# STM32L15xxE register map
File version: 1.0
CPU: 
Registers are 32-bit, read-write, reset 0x0 unless marked. A register's access mark holds for its fields unless they carry their own. Offsets are from the block's base; [hi:lo] are bit positions; {n}, {i} and the like mark numbered series.

## LCD — Liquid crystal display controller
Base 0x40002400
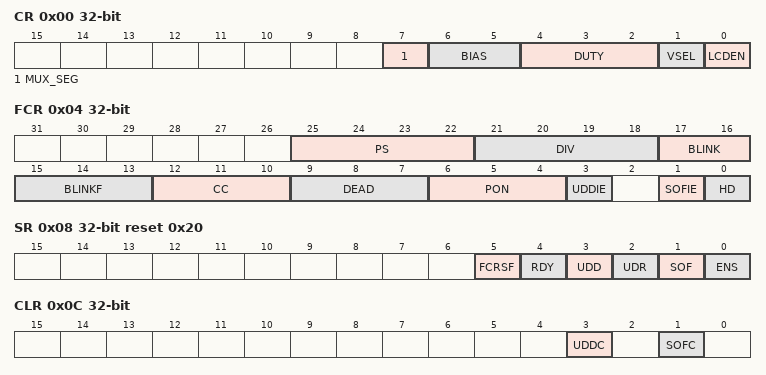
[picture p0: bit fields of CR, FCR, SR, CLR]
0x00 CR — control register
  [7] MUX_SEG — Mux segment enable
  [6:5] BIAS — Bias selector
  [4:2] DUTY — Duty selection
  [1] VSEL — Voltage source selection
  [0] LCDEN — LCD controller enable
0x04 FCR — frame control register
  [25:22] PS — PS 16-bit prescaler
  [21:18] DIV — DIV clock divider
  [17:16] BLINK — Blink mode selection
  [15:13] BLINKF — Blink frequency selection
  [12:10] CC — Contrast control
  [9:7] DEAD — Dead time duration
  [6:4] PON — Pulse ON duration
  [3] UDDIE — Update display done interrupt enable
  [1] SOFIE — Start of frame interrupt enable
  [0] HD — High drive enable
0x08 SR access per field reset 0x20 — status register
  [5] FCRSF ro — LCD Frame Control Register Synchronization flag
  [4] RDY ro — Ready flag
  [3] UDD ro — Update Display Done
  [2] UDR rw — Update display request
  [1] SOF ro — Start of frame flag
  [0] ENS ro — LCD enabled status
0x0C CLR wo — clear register
  [3] UDDC — Update display done clear
  [1] SOFC — Start of frame flag clear
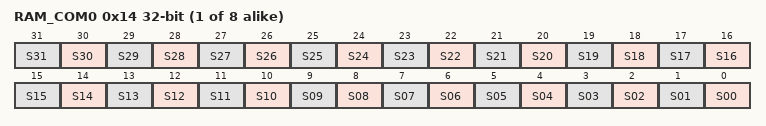
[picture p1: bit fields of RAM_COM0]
{0x14+8i} RAM_COM{i} (i=0..7) — display memory
  [n] S{n:02} (n=0..31)

## NVIC — Nested Vectored Interrupt Controller
Base 0xE000E000
0x04 ICTR ro — Interrupt Controller Type Register
  [3:0] INTLINESNUM — Total number of interrupt lines in groups
0x100 ISER0 — Interrupt Set-Enable Register
  [31:0] SETENA
0x104 ISER1 — Interrupt Set-Enable Register
  [31:0] SETENA
0x180 ICER0 — Interrupt Clear-Enable Register
  [31:0] CLRENA
0x184 ICER1 — Interrupt Clear-Enable Register
  [31:0] CLRENA
0x200 ISPR0 — Interrupt Set-Pending Register
  [31:0] SETPEND
0x204 ISPR1 — Interrupt Set-Pending Register
  [31:0] SETPEND
0x280 ICPR0 — Interrupt Clear-Pending Register
  [31:0] CLRPEND
0x284 ICPR1 — Interrupt Clear-Pending Register
  [31:0] CLRPEND
0x300 IABR0 ro — Interrupt Active Bit Register
  [31:0] ACTIVE
0x304 IABR1 ro — Interrupt Active Bit Register
  [31:0] ACTIVE
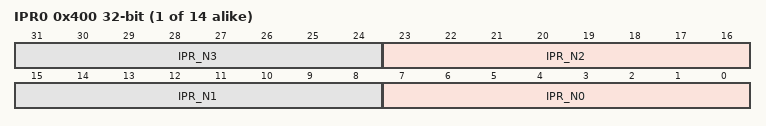
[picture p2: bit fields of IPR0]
{0x400+4i} IPR{i} (i=0..13) — Interrupt Priority Register
  [8n+7:8n] IPR_N{n} (n=0..3)
0xF00 STIR wo — Software Triggered Interrupt Register
  [8:0] INTID — interrupt to be triggered

## PWR — Power control
Base 0x40007000
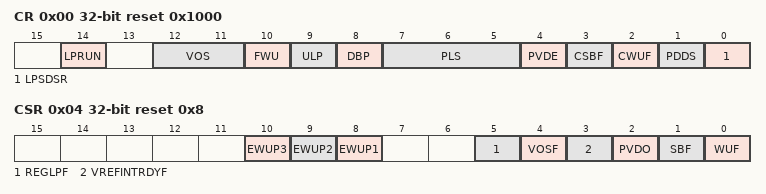
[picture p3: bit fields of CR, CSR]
0x00 CR reset 0x1000 — power control register
  [14] LPRUN — Low power run mode
  [12:11] VOS — Voltage scaling range selection
  [10] FWU — Fast wakeup
  [9] ULP — Ultralow power mode
  [8] DBP — Disable backup domain write protection
  [7:5] PLS — PVD level selection
  [4] PVDE — Power voltage detector enable
  [3] CSBF — Clear standby flag
  [2] CWUF — Clear wakeup flag
  [1] PDDS — Power down deepsleep
  [0] LPSDSR — Low-power deep sleep
0x04 CSR access per field reset 0x8 — power control/status register
  [10] EWUP3 rw — Enable WKUP pin 3
  [9] EWUP2 rw — Enable WKUP pin 2
  [8] EWUP1 rw — Enable WKUP pin 1
  [5] REGLPF ro — Regulator LP flag
  [4] VOSF ro — Voltage Scaling select flag
  [3] VREFINTRDYF ro — Internal voltage reference (VREFINT) ready flag
  [2] PVDO ro — PVD output
  [1] SBF ro — Standby flag
  [0] WUF ro — Wakeup flag

## SPI2 — Serial peripheral interface
Base 0x40003800
Same registers: SPI1 0x40013000, SPI3 0x40013C00
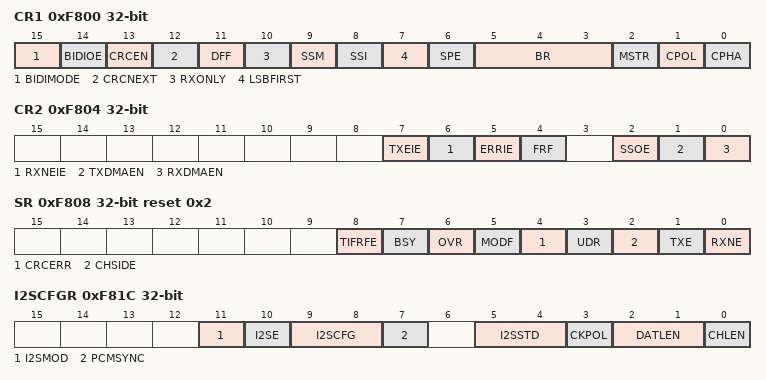
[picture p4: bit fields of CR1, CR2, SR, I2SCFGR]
0xF800 CR1 — control register 1
  [15] BIDIMODE — Bidirectional data mode enable
  [14] BIDIOE — Output enable in bidirectional mode
  [13] CRCEN — Hardware CRC calculation enable
  [12] CRCNEXT — CRC transfer next
  [11] DFF — Data frame format
  [10] RXONLY — Receive only
  [9] SSM — Software slave management
  [8] SSI — Internal slave select
  [7] LSBFIRST — Frame format
  [6] SPE — SPI enable
  [5:3] BR — Baud rate control
  [2] MSTR — Master selection
  [1] CPOL — Clock polarity
  [0] CPHA — Clock phase
0xF804 CR2 — control register 2
  [7] TXEIE — Tx buffer empty interrupt enable
  [6] RXNEIE — RX buffer not empty interrupt enable
  [5] ERRIE — Error interrupt enable
  [4] FRF — Frame format
  [2] SSOE — SS output enable
  [1] TXDMAEN — Tx buffer DMA enable
  [0] RXDMAEN — Rx buffer DMA enable
0xF808 SR access per field reset 0x2 — status register
  [8] TIFRFE ro — TI frame format error
  [7] BSY ro — Busy flag
  [6] OVR ro — Overrun flag
  [5] MODF ro — Mode fault
  [4] CRCERR rw — CRC error flag
  [3] UDR ro — Underrun flag
  [2] CHSIDE ro — Channel side
  [1] TXE ro — Transmit buffer empty
  [0] RXNE ro — Receive buffer not empty
0xF80C DR — data register
  [15:0] DR — Data register
0xF810 CRCPR reset 0x7 — CRC polynomial register
  [15:0] CRCPOLY
0xF814 RXCRCR ro — RX CRC register
  [15:0] RxCRC
0xF818 TXCRCR ro — TX CRC register
  [15:0] TxCRC
0xF81C I2SCFGR — I2S configuration register
  [11] I2SMOD — I2S mode selection
  [10] I2SE — I2S Enable
  [9:8] I2SCFG — I2S configuration mode
  [7] PCMSYNC — PCM frame synchronization
  [5:4] I2SSTD — I2S standard selection
  [3] CKPOL — Steady state clock polarity
  [2:1] DATLEN — Data length to be transferred
  [0] CHLEN — Channel length (number of bits per audio channel)
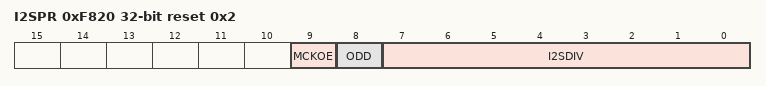
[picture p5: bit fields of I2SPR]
0xF820 I2SPR reset 0x2 — I2S prescaler register
  [9] MCKOE — Master clock output enable
  [8] ODD — Odd factor for the prescaler
  [7:0] I2SDIV — I2S Linear prescaler
